VERSION "0.0"

NS_ :

                BA_DiEF_
                BA_
                CAT_DEF_
                CAT_
                FILTER
                BA_DEF_DEF_
                EV_DATA_
                ENVVAR_DATA_
                SGTYPE_
                SGTYPE_VAL_
                BA_DEF_SGTYPE_
                BA_SGTYPE_
                SIG_TYPE_REF_
                VAL_TABLE_
                SIG_GROUP_
                SIG_VALTYPE_
                SIGTYPE_VALTYPE_
                BO_TX_BU_
                BA_DEF_REL_
                BA_REL_
                BA_DEF_DEF_REL_
                BU_SG_REL_
                BU_EV_REL_
                BU_BO_REL_
                SG_MUL_VAL_

		NS_DESC_
                CM_
                BA_DEF_
                BA_
                CAT_DEF_
                CAT_
                FILTER
                BA_DEF_DEF_
                EV_DATA_
                ENVVAR_DATA_
                SGTYPE_
                SGTYPE_VAL_
                BA_DEF_SGTYPE_
                BA_SGTYPE_
                SIG_TYPE_REF_
                VAL_TABLE_
                SIG_GROUP_
                SIG_VALTYPE_
                SIGTYPE_VALTYPE_
                BO_TX_BU_
                BA_DEF_REL_
                BA_REL_
                BA_DEF_DEF_REL_
                BU_SG_REL_
                BU_EV_REL_
                BU_BO_REL_
                SG_MUL_VAL_

		NS_DESC_
                CM_
                BA_DEF_
                BA_
                CAT_DEF_
                CAT_
                FILTER
                BA_DEF_DEF_
                EV_DATA_
                ENVVAR_DATA_
                SGTYPE_
                SGTYPE_VAL_
                BA_DEF_SGTYPE_
                BA_SGTYPE_
                SIG_TYPE_REF_
                VAL_TABLE_
                SIG_GROUP_
                SIG_VALTYPE_
                SIGTYPE_VALTYPE_
                BO_TX_BU_
                BA_DEF_REL_
                BA_REL_
                BA_DEF_DEF_REL_
                BU_SG_REL_
                BU_EV_REL_
                BU_BO_REL_
                SG_MUL_VAL_

BS_:

BU_:

BO_ 1024 MC_Identification: 8 Vector__XXX
        SG_ Prohelion_ID : 0|32@1+ (1,0) [0|0] "" Vector__XXX
        SG_ Serial_Number : 32|32@1+ (1,0) [0|0] "" Vector__XXX

BO_ 1025 MC_Status: 8 Vector__XXX
        SG_ Output_Voltage_PWM_Limit : 0|1@1+ (1,0) [0|0] "" Vector__XXX
        SG_ Motor_Current_Limit : 1|1@1+ (1,0) [0|0] "" Vector__XXX
        SG_ Velocity_Limit : 2|1@1+ (1,0) [0|0] "" Vector__XXX
        SG_ Bus_Current_Limit : 3|1@1+ (1,0) [0|0] "" Vector__XXX
        SG_ Bus_Voltage_U_Limit : 4|1@1+ (1,0) [0|0] "" Vector__XXX
        SG_ Bus_Voltage_L_Limit : 5|1@1+ (1,0) [0|0] "" Vector__XXX
        SG_ Motor_Temperature_Limit : 6|1@1+ (1,0) [0|0] "" Vector__XXX
        SG_ Hardware_Over_Current : 16|1@1+ (1,0) [0|0] "" Vector__XXX
        SG_ Software_Over_Current : 17|1@1+ (1,0) [0|0] "" Vector__XXX
        SG_ Bus_Overvoltage : 18|1@1+ (1,0) [0|0] "" Vector__XXX
        SG_ Bad_Hall_Sequence : 19|1@1+ (1,0) [0|0] "" Vector__XXX
        SG_ Watchdog_Reset : 20|1@1+ (1,0) [0|0] "" Vector__XXX
        SG_ Config_Read_Error : 21|1@1+ (1,0) [0|0] "" Vector__XXX
        SG_ UVLO_15V : 22|1@1+ (1,0) [0|0] "" Vector__XXX
        SG_ Desaturation_Fault : 23|1@1+ (1,0) [0|0] "" Vector__XXX
        SG_ Motor_Over_Speed : 24|1@1+ (1,0) [0|0] "" Vector__XXX
        SG_ Active_Motor : 32|16@1+ (1,0) [0|0] "" Vector__XXX
        SG_ Transmit_Error_Count : 48|8@1+ (1,0) [0|0] "" Vector__XXX
        SG_ Receive_Error_Count : 56|8@1+ (1,0) [0|0] "" Vector__XXX

BO_ 1026 MC_Bus_Measurement: 8 Vector__XXX
        SG_ Bus_Voltage : 0|32@1+ (1,0) [0|0] "Volt" Vector__XXX
        SG_ Bus_Current : 32|32@1+ (1,0) [0|0] "Ampere" Vector__XXX

BO_ 1027 MC_Velocity: 8 Vector__XXX
        SG_ Motor_Velocity : 0|32@1+ (1,0) [0|0] "RPM" Vector__XXX
        SG_ Vehicle_Velocity : 32|32@1+ (1,0) [0|0] "m/s" Vector__XXX

BO_ 1028 MC_Phase_Current: 8 Vector__XXX
        SG_ PhaseC_Current_Val : 32|32@1+ (1,0) [0|0] "Ampere" Vector__XXX
        SG_ PhaseB_Current_Val : 0|32@1+ (1,0) [0|0] "Ampere" Vector__XXX

BO_ 1029 MC_Motor_Voltage_Vector: 8 Vector__XXX
        SG_ Vq : 0|32@1+ (1,0) [0|0] "Volt" Vector__XXX
        SG_ Vd : 32|32@1+ (1,0) [0|0] "Volt" Vector__XXX

BO_ 1030 MC_Motor_Current_Vector: 8 Vector__XXX
        SG_ Iq : 0|32@1+ (1,0) [0|0] "Ampere" Vector__XXX
        SG_ Id : 32|32@1+ (1,0) [0|0] "Ampere" Vector__XXX

BO_ 1031 MC_BackEMF: 8 Vector__XXX
        SG_ BEMFq : 0|32@1+ (1,0) [0|0] "Volt" Vector__XXX
        SG_ BEMFd : 32|32@1+ (1,0) [0|0] "Volt" Vector__XXX

BO_ 1032 MC_Voltage_Rail_15V: 8 Vector__XXX
        SG_ Supply_15V : 32|32@1+ (1,0) [0|0] "Volt" Vector__XXX

BO_ 1033 MC_Voltage_Rail_3V3_1V9: 8 Vector__XXX
        SG_ Supply_1V9 : 0|32@1+ (1,0) [0|0] "" Vector__XXX
        SG_ Supply_3V3 : 32|32@1+ (1,0) [0|0] "" Vector__XXX

BO_ 1035 MC_HeatSink_Motor_Temperature: 8 Vector__XXX
        SG_ Motor_Temp : 0|32@1+ (1,0) [0|0] "Celcius" Vector__XXX
        SG_ Heat_Sink_Temp : 32|32@1+ (1,0) [0|0] "Celcius" Vector__XXX

BO_ 1036 MC_DSP_Temperature: 8 Vector__XXX
        SG_ DSP_Board_Temperature : 0|32@1+ (1,0) [0|0] "Celcius" Vector__XXX

BO_ 1038 MC_Odometer_Charge: 8 Vector__XXX
        SG_ Odometer : 0|32@1+ (1,0) [0|0] "meter" Vector__XXX
        SG_ DC_Bus_AmpHours : 32|32@1+ (1,0) [0|0] "Ah" Vector__XXX

BO_ 1047 MC_Slip_Speed: 8 Vector__XXX
        SG_ Slip_Speed : 32|32@1+ (1,0) [0|0] "Hz" Vector__XXX

BO_ 1042 MC_Active_Motor_Change: 8 Vector__XXX
        SG_ Config_Key : 0|32@1+ (1,0) [0|0] "" Vector__XXX
        SG_ Active_Motor : 32|32@1+ (1,0) [0|0] "" Vector__XXX

BO_ 1696 MPPT1_Input_Measurements: 8 Vector__XXX
        SG_ Input_Voltage_A : 0|32@1+ (1,0) [0|0] "Volt" Vector__XXX
        SG_ Input_Current_A : 32|32@1+ (1,0) [0|0] "Ampere" Vector__XXX

BO_ 1697 MPPT1_Output_Measurements: 8 Vector__XXX
        SG_ Output_Voltage_A : 0|32@1+ (1,0) [0|0] "Volt" Vector__XXX
        SG_ Output_Current_A : 32|32@1+ (1,0) [0|0] "Ampere" Vector__XXX

BO_ 1698 MPPT1_Temperature: 8 Vector__XXX
        SG_ MOSFET_Temp_A : 0|32@1+ (1,0) [0|0] "Celcius" Vector__XXX
        SG_ Controller_Temp_A : 32|32@1+ (1,0) [0|0] "" Vector__XXX

BO_ 1699 MPPT1_Auxiliary_PS: 8 Vector__XXX
        SG_ Supply_12V_A : 0|32@1+ (1,0) [0|0] "Volt" Vector__XXX
        SG_ Supply_3V_A : 32|32@1+ (1,0) [0|0] "Volt" Vector__XXX

BO_ 1700 MPPT1_Limits: 8 Vector__XXX
        SG_ Max_Out_Volt_A : 0|32@1+ (1,0) [0|0] "Volt" Vector__XXX
        SG_ Max_In_Current_A : 32|32@1+ (1,0) [0|0] "Ampere" Vector__XXX

BO_ 1701 MPPT1_Status: 8 Vector__XXX
        SG_ RX_Error_Count_A : 0|8@1+ (1,0) [0|0] "" Vector__XXX
        SG_ TX_Error_Count_A : 8|8@1+ (1,0) [0|0] "" Vector__XXX
        SG_ TX_Overflow_Count_A : 16|8@1+ (1,0) [0|0] "" Vector__XXX
        SG_ Low_Array_Power_A : 24|1@1+ (1,0) [0|0] "" Vector__XXX
        SG_ Mosfet_Overheat_A : 25|1@1+ (1,0) [0|0] "" Vector__XXX
        SG_ Battery_Low_A : 26|1@1+ (1,0) [0|0] "" Vector__XXX
        SG_ Battery_Full_A : 27|1@1+ (1,0) [0|0] "" Vector__XXX
        SG_ Undervoltage_12V_A : 28|1@1+ (1,0) [0|0] "" Vector__XXX
        SG_ HW_Overcurrent_A : 30|1@1+ (1,0) [0|0] "" Vector__XXX
        SG_ HW_Overvoltage_A : 31|1@1+ (1,0) [0|0] "" Vector__XXX
        SG_ Input_Currnet_Min_A : 32|1@1+ (1,0) [0|0] "" Vector__XXX
        SG_ Input_Current_Max_A : 33|1@1+ (1,0) [0|0] "" Vector__XXX
        SG_ Output_Voltage_Max_A : 34|1@1+ (1,0) [0|0] "" Vector__XXX
        SG_ MOSFET_Temperature_A : 35|1@1+ (1,0) [0|0] "" Vector__XXX
        SG_ Duty_Cycle_Min_A : 36|1@1+ (1,0) [0|0] "" Vector__XXX
        SG_ Duty_Cycle_Max_A : 37|1@1+ (1,0) [0|0] "" Vector__XXX
        SG_ Local_MPPT_A : 38|1@1+ (1,0) [0|0] "" Vector__XXX
        SG_ Global_MPPT_A : 39|1@1+ (1,0) [0|0] "" Vector__XXX
        SG_ Mode_A : 40|8@1+ (1,0) [0|0] "" Vector__XXX
        SG_ Test_Counter_A : 56|8@1+ (1,0) [0|0] "" Vector__XXX

BO_ 1702 MPPT1_Power_Connector: 8 Vector__XXX
        SG_ Battery_Side_Output_Voltage_A : 0|32@1+ (1,0) [0|0] "Volt" Vector__XXX
        SG_ Power_Connector_Temperature_A : 32|32@1+ (1,0) [0|0] "Celcius" Vector__XXX

BO_ 1704 MPPT1_Mode_Set: 1 Vector__XXX
        SG_ Set_Mode_A : 0|8@1+ (1,0) [0|0] "" Vector__XXX

BO_ 1706 MPPT1_Maximum_Output_Volt: 4 Vector__XXX
        SG_ Max_Output_Voltage_Set_A : 0|32@1+ (1,0) [0|0] "Volt" Vector__XXX

BO_ 1707 MPPT1_Maximum_Input_Current: 4 Vector__XXX
        SG_ Max_Input_Current_Set_A : 0|32@1+ (1,0) [0|0] "Ampere" Vector__XXX

BO_ 1712 MPPT2_Input_Measurements: 8 Vector__XXX
        SG_ Input_Voltage_B : 0|32@1+ (1,0) [0|0] "Volt" Vector__XXX
        SG_ Input_Current_B : 32|32@1+ (1,0) [0|0] "Ampere" Vector__XXX

BO_ 1713 MPPT2_Output_Measurements: 8 Vector__XXX
        SG_ Output_Voltage_B : 0|32@1+ (1,0) [0|0] "Volt" Vector__XXX
        SG_ Output_Current_B : 32|32@1+ (1,0) [0|0] "Ampere" Vector__XXX

BO_ 1714 MPPT2_Temperature: 8 Vector__XXX
        SG_ MOSFET_Temp_B : 0|32@1+ (1,0) [0|0] "Celcius" Vector__XXX
        SG_ Controller_Temp_B : 32|32@1+ (1,0) [0|0] "" Vector__XXX

BO_ 1715 MPPT2_Auxiliary_PS: 8 Vector__XXX
        SG_ Supply_12V_B : 0|32@1+ (1,0) [0|0] "Volt" Vector__XXX
        SG_ Supply_3V_B : 32|32@1+ (1,0) [0|0] "Volt" Vector__XXX

BO_ 1716 MPPT2_Limits: 8 Vector__XXX
        SG_ Max_Out_Volt_B : 0|32@1+ (1,0) [0|0] "Volt" Vector__XXX
        SG_ Max_In_Current_B : 32|32@1+ (1,0) [0|0] "Ampere" Vector__XXX

BO_ 1717 MPPT2_Status: 8 Vector__XXX
        SG_ RX_Error_Count_B : 0|8@1+ (1,0) [0|0] "" Vector__XXX
        SG_ TX_Error_Count_B : 8|8@1+ (1,0) [0|0] "" Vector__XXX
        SG_ TX_Overflow_Count_B : 16|8@1+ (1,0) [0|0] "" Vector__XXX
        SG_ Low_Array_Power_B : 24|1@1+ (1,0) [0|0] "" Vector__XXX
        SG_ Mosfet_Overheat_B : 25|1@1+ (1,0) [0|0] "" Vector__XXX
        SG_ Battery_Low_B : 26|1@1+ (1,0) [0|0] "" Vector__XXX
        SG_ Undervoltage_12V_B : 28|1@1+ (1,0) [0|0] "" Vector__XXX
        SG_ Battery_Full_B : 27|1@1+ (1,0) [0|0] "" Vector__XXX
        SG_ HW_Overcurrent_B : 30|1@1+ (1,0) [0|0] "" Vector__XXX
        SG_ HW_Overvoltage_B : 31|1@1+ (1,0) [0|0] "" Vector__XXX
        SG_ Input_Currnet_Min_B : 32|1@1+ (1,0) [0|0] "" Vector__XXX
        SG_ Input_Current_Max_B : 33|1@1+ (1,0) [0|0] "" Vector__XXX
        SG_ Output_Voltage_Max_B : 34|1@1+ (1,0) [0|0] "" Vector__XXX
        SG_ MOSFET_Temperature_B : 35|1@1+ (1,0) [0|0] "" Vector__XXX
        SG_ Duty_Cycle_Min_B : 36|1@1+ (1,0) [0|0] "" Vector__XXX
        SG_ Duty_Cycle_Max_B : 37|1@1+ (1,0) [0|0] "" Vector__XXX
        SG_ Local_MPPT_B : 38|1@1+ (1,0) [0|0] "" Vector__XXX
        SG_ Global_MPPT_B : 39|1@1+ (1,0) [0|0] "" Vector__XXX
        SG_ Mode_B : 40|8@1+ (1,0) [0|0] "" Vector__XXX
        SG_ Test_Counter_B : 56|8@1+ (1,0) [0|0] "" Vector__XXX

BO_ 1718 MPPT2_Power_Connector: 8 Vector__XXX
        SG_ Battery_Side_Output_Voltage_B : 0|32@1+ (1,0) [0|0] "Volt" Vector__XXX
        SG_ Power_Connector_Temperature_B : 32|32@1+ (1,0) [0|0] "Celcius" Vector__XXX

BO_ 1720 MPPT2_Mode_Set: 1 Vector__XXX
        SG_ Set_Mode_B : 0|8@1+ (1,0) [0|0] "" Vector__XXX

BO_ 1722 MPPT2_Maximum_Output_Volt: 4 Vector__XXX
        SG_ Max_Output_Voltage_Set_B : 0|32@1+ (1,0) [0|0] "Volt" Vector__XXX

BO_ 1723 MPPT2_Maximum_Input_Current: 4 Vector__XXX
        SG_ Max_Input_Current_Set_B : 0|32@1+ (1,0) [0|0] "Ampere" Vector__XXX

BO_ 1728 MPPT3_Input_Measurements: 8 Vector__XXX
        SG_ Input_Voltage_C : 0|32@1+ (1,0) [0|0] "Volt" Vector__XXX
        SG_ Input_Current_C : 32|32@1+ (1,0) [0|0] "Ampere" Vector__XXX

BO_ 1729 MPPT3_Output_Measurements: 8 Vector__XXX
        SG_ Output_Voltage_C : 0|32@1+ (1,0) [0|0] "Volt" Vector__XXX
        SG_ Output_Current_C : 32|32@1+ (1,0) [0|0] "Ampere" Vector__XXX

BO_ 1730 MPPT3_Temperature: 8 Vector__XXX
        SG_ MOSFET_Temp_C : 0|32@1+ (1,0) [0|0] "Celcius" Vector__XXX
        SG_ Controller_Temp_C : 32|32@1+ (1,0) [0|0] "" Vector__XXX

BO_ 1731 MPPT3_Auxiliary_PS: 8 Vector__XXX
        SG_ Supply_12V_C : 0|32@1+ (1,0) [0|0] "Volt" Vector__XXX
        SG_ Supply_3V_C : 32|32@1+ (1,0) [0|0] "Volt" Vector__XXX

BO_ 1732 MPPT3_Limits: 8 Vector__XXX
        SG_ Max_Out_Volt_C : 0|32@1+ (1,0) [0|0] "Volt" Vector__XXX
        SG_ Max_In_Current_C : 32|32@1+ (1,0) [0|0] "Ampere" Vector__XXX

BO_ 1733 MPPT3_Status: 8 Vector__XXX
        SG_ RX_Error_Count_C : 0|8@1+ (1,0) [0|0] "" Vector__XXX
        SG_ TX_Error_Count_C : 8|8@1+ (1,0) [0|0] "" Vector__XXX
        SG_ TX_Overflow_Count_C : 16|8@1+ (1,0) [0|0] "" Vector__XXX
        SG_ Low_Array_Power_C : 24|1@1+ (1,0) [0|0] "" Vector__XXX
        SG_ Mosfet_Overheat_C : 25|1@1+ (1,0) [0|0] "" Vector__XXX
        SG_ Battery_Low_C : 26|1@1+ (1,0) [0|0] "" Vector__XXX
        SG_ Undervoltage_12V_C : 28|1@1+ (1,0) [0|0] "" Vector__XXX
        SG_ Battery_Full_C : 27|1@1+ (1,0) [0|0] "" Vector__XXX
        SG_ HW_Overcurrent_C : 30|1@1+ (1,0) [0|0] "" Vector__XXX
        SG_ HW_Overvoltage_C : 31|1@1+ (1,0) [0|0] "" Vector__XXX
        SG_ Input_Currnet_Min_C : 32|1@1+ (1,0) [0|0] "" Vector__XXX
        SG_ Input_Current_Max_C : 33|1@1+ (1,0) [0|0] "" Vector__XXX
        SG_ Output_Voltage_Max_C : 34|1@1+ (1,0) [0|0] "" Vector__XXX
        SG_ MOSFET_Temperature_C : 35|1@1+ (1,0) [0|0] "" Vector__XXX
        SG_ Duty_Cycle_Min_C : 36|1@1+ (1,0) [0|0] "" Vector__XXX
        SG_ Duty_Cycle_Max_C : 37|1@1+ (1,0) [0|0] "" Vector__XXX
        SG_ Local_MPPT_C : 38|1@1+ (1,0) [0|0] "" Vector__XXX
        SG_ Global_MPPT_C : 39|1@1+ (1,0) [0|0] "" Vector__XXX
        SG_ Mode_C : 40|8@1+ (1,0) [0|0] "" Vector__XXX
        SG_ Test_Counter_C : 56|8@1+ (1,0) [0|0] "" Vector__XXX

BO_ 1734 MPPT3_Power_Connector: 8 Vector__XXX
        SG_ Battery_Side_Output_Voltage_C : 0|32@1+ (1,0) [0|0] "Volt" Vector__XXX
        SG_ Power_Connector_Temperature_C : 32|32@1+ (1,0) [0|0] "Celcius" Vector__XXX

BO_ 1736 MPPT3_Mode_Set: 1 Vector__XXX
        SG_ Set_Mode_C : 0|8@1+ (1,0) [0|0] "" Vector__XXX

BO_ 1738 MPPT3_Maximum_Output_Volt: 4 Vector__XXX
        SG_ Max_Output_Voltage_Set_C : 0|32@1+ (1,0) [0|0] "Volt" Vector__XXX

BO_ 1739 MPPT3_Maximum_Input_Current: 4 Vector__XXX
        SG_ Max_Input_Current_Set_C : 0|32@1+ (1,0) [0|0] "Ampere" Vector__XXX

BO_ 1744 MPPT4_Input_Measurements: 8 Vector__XXX
        SG_ Input_Voltage_D : 0|32@1+ (1,0) [0|0] "Volt" Vector__XXX
        SG_ Input_Current_D : 32|32@1+ (1,0) [0|0] "Ampere" Vector__XXX

BO_ 1745 MPPT4_Output_Measurements: 8 Vector__XXX
        SG_ Output_Voltage_D : 0|32@1+ (1,0) [0|0] "Volt" Vector__XXX
        SG_ Output_Current_D : 32|32@1+ (1,0) [0|0] "Ampere" Vector__XXX

BO_ 1746 MPPT4_Temperature: 8 Vector__XXX
        SG_ MOSFET_Temp_D : 0|32@1+ (1,0) [0|0] "Celcius" Vector__XXX
        SG_ Controller_Temp_D : 32|32@1+ (1,0) [0|0] "" Vector__XXX

BO_ 1747 MPPT4_Auxiliary_PS: 8 Vector__XXX
        SG_ Supply_12V_D : 0|32@1+ (1,0) [0|0] "Volt" Vector__XXX
        SG_ Supply_3V_D : 32|32@1+ (1,0) [0|0] "Volt" Vector__XXX

BO_ 1748 MPPT4_Limits: 8 Vector__XXX
        SG_ Max_Out_Volt_D : 0|32@1+ (1,0) [0|0] "Volt" Vector__XXX
        SG_ Max_In_Current_D : 32|32@1+ (1,0) [0|0] "Ampere" Vector__XXX

BO_ 1749 MPPT4_Status: 8 Vector__XXX
        SG_ RX_Error_Count_D : 0|8@1+ (1,0) [0|0] "" Vector__XXX
        SG_ TX_Error_Count_D : 8|8@1+ (1,0) [0|0] "" Vector__XXX
        SG_ TX_Overflow_Count_D : 16|8@1+ (1,0) [0|0] "" Vector__XXX
        SG_ Low_Array_Power_D : 24|1@1+ (1,0) [0|0] "" Vector__XXX
        SG_ Mosfet_Overheat_D : 25|1@1+ (1,0) [0|0] "" Vector__XXX
        SG_ Battery_Low_D : 26|1@1+ (1,0) [0|0] "" Vector__XXX
        SG_ Undervoltage_12V_D : 28|1@1+ (1,0) [0|0] "" Vector__XXX
        SG_ Battery_Full_D : 27|1@1+ (1,0) [0|0] "" Vector__XXX
        SG_ HW_Overcurrent_D : 30|1@1+ (1,0) [0|0] "" Vector__XXX
        SG_ HW_Overvoltage_D : 31|1@1+ (1,0) [0|0] "" Vector__XXX
        SG_ Input_Currnet_Min_D : 32|1@1+ (1,0) [0|0] "" Vector__XXX
        SG_ Input_Current_Max_D : 33|1@1+ (1,0) [0|0] "" Vector__XXX
        SG_ Output_Voltage_Max_D : 34|1@1+ (1,0) [0|0] "" Vector__XXX
        SG_ MOSFET_Temperature_D : 35|1@1+ (1,0) [0|0] "" Vector__XXX
        SG_ Duty_Cycle_Min_D : 36|1@1+ (1,0) [0|0] "" Vector__XXX
        SG_ Duty_Cycle_Max_D : 37|1@1+ (1,0) [0|0] "" Vector__XXX
        SG_ Local_MPPT_D : 38|1@1+ (1,0) [0|0] "" Vector__XXX
        SG_ Global_MPPT_D : 39|1@1+ (1,0) [0|0] "" Vector__XXX
        SG_ Mode_D : 40|8@1+ (1,0) [0|0] "" Vector__XXX
        SG_ Test_Counter_D : 56|8@1+ (1,0) [0|0] "" Vector__XXX

BO_ 1750 MPPT4_Power_Connector: 8 Vector__XXX
        SG_ Battery_Side_Output_Voltage_D : 0|32@1+ (1,0) [0|0] "Volt" Vector__XXX
        SG_ Power_Connector_Temperature_D : 32|32@1+ (1,0) [0|0] "Celcius" Vector__XXX

BO_ 1752 MPPT4_Mode_Set: 1 Vector__XXX
        SG_ Set_Mode_D : 0|8@1+ (1,0) [0|0] "" Vector__XXX

BO_ 1754 MPPT4_Maximum_Output_Volt: 4 Vector__XXX
        SG_ Max_Output_Voltage_Set_D : 0|32@1+ (1,0) [0|0] "Volt" Vector__XXX

BO_ 1755 MPPT4_Maximum_Input_Current: 4 Vector__XXX
        SG_ Max_Input_Current_Set_D : 0|32@1+ (1,0) [0|0] "Ampere" Vector__XXX

BO_ 1285 Driver_Controls: 8 Vector__XXX
        SG_ State : 0|16@1+ (1,0) [0|0] "" Vector__XXX

BO_ 1536 Heartbeat: 8 Vector__XXX
	SG_ Device_ID : 0|32@1+ (1,0) [0|0] "" Vector__XXX
	SG_ Serial_No : 32|32@1+ (1,0) [0|0] "" Vector__XXX

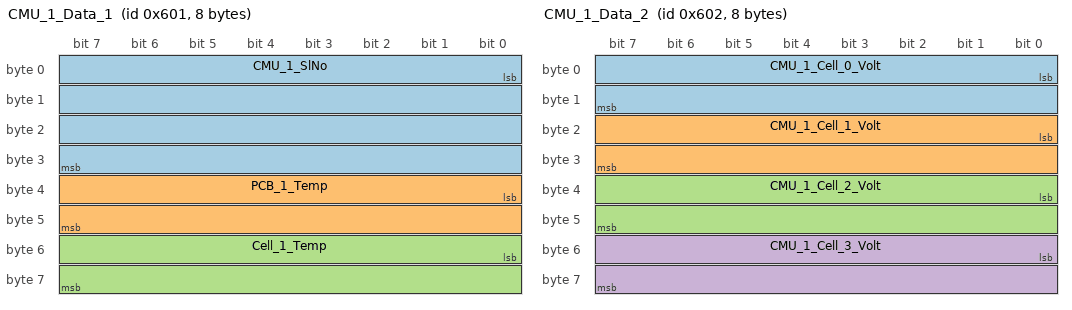
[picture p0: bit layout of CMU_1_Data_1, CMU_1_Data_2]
BO_ 1537 CMU_1_Data_1: 8 Vector__XXX
        SG_ CMU_1_SlNo : 0|32@1+ (1,0) [0|0] "" Vector__XXX
        SG_ PCB_1_Temp : 32|16@1+ (0.1,0) [0|0] "Celcius" Vector__XXX
        SG_ Cell_1_Temp : 48|16@1+ (0.1,0) [0|0] "Celcius" Vector__XXX

BO_ 1538 CMU_1_Data_2: 8 Vector__XXX
        SG_ CMU_1_Cell_0_Volt : 0|16@1+ (1,0) [0|0] "mV" Vector__XXX
        SG_ CMU_1_Cell_1_Volt : 16|16@1+ (1,0) [0|0] "mV" Vector__XXX
        SG_ CMU_1_Cell_2_Volt : 32|16@1+ (1,0) [0|0] "mV" Vector__XXX
        SG_ CMU_1_Cell_3_Volt : 48|16@1+ (1,0) [0|0] "mV" Vector__XXX

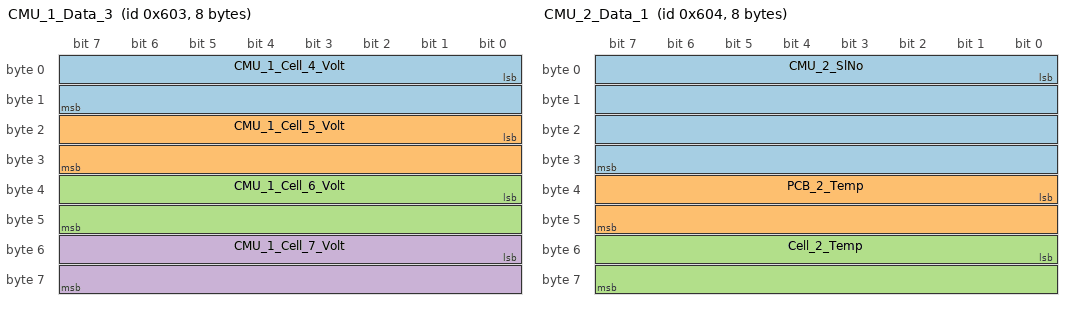
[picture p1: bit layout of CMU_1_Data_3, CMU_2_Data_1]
BO_ 1539 CMU_1_Data_3: 8 Vector__XXX
        SG_ CMU_1_Cell_4_Volt : 0|16@1+ (1,0) [0|0] "mV" Vector__XXX
        SG_ CMU_1_Cell_5_Volt : 16|16@1+ (1,0) [0|0] "mV" Vector__XXX
        SG_ CMU_1_Cell_6_Volt : 32|16@1+ (1,0) [0|0] "mV" Vector__XXX
        SG_ CMU_1_Cell_7_Volt : 48|16@1+ (1,0) [0|0] "mV" Vector__XXX

BO_ 1540 CMU_2_Data_1: 8 Vector__XXX
        SG_ CMU_2_SlNo : 0|32@1+ (1,0) [0|0] "" Vector__XXX
        SG_ PCB_2_Temp : 32|16@1+ (0.1,0) [0|0] "Celcius" Vector__XXX
        SG_ Cell_2_Temp : 48|16@1+ (0.1,0) [0|0] "Celcius" Vector__XXX

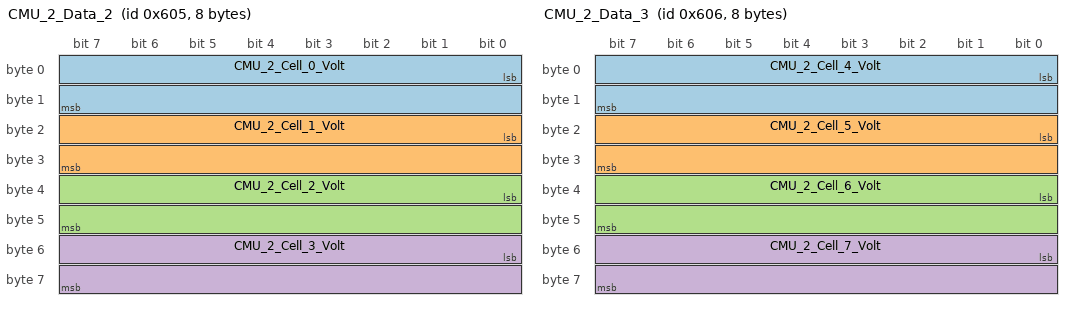
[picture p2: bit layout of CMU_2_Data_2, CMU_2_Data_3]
BO_ 1541 CMU_2_Data_2: 8 Vector__XXX
        SG_ CMU_2_Cell_0_Volt : 0|16@1+ (1,0) [0|0] "mV" Vector__XXX
        SG_ CMU_2_Cell_1_Volt : 16|16@1+ (1,0) [0|0] "mV" Vector__XXX
        SG_ CMU_2_Cell_2_Volt : 32|16@1+ (1,0) [0|0] "mV" Vector__XXX
        SG_ CMU_2_Cell_3_Volt : 48|16@1+ (1,0) [0|0] "mV" Vector__XXX

BO_ 1542 CMU_2_Data_3: 8 Vector__XXX
        SG_ CMU_2_Cell_4_Volt : 0|16@1+ (1,0) [0|0] "mV" Vector__XXX
        SG_ CMU_2_Cell_5_Volt : 16|16@1+ (1,0) [0|0] "mV" Vector__XXX
        SG_ CMU_2_Cell_6_Volt : 32|16@1+ (1,0) [0|0] "mV" Vector__XXX
        SG_ CMU_2_Cell_7_Volt : 48|16@1+ (1,0) [0|0] "mV" Vector__XXX

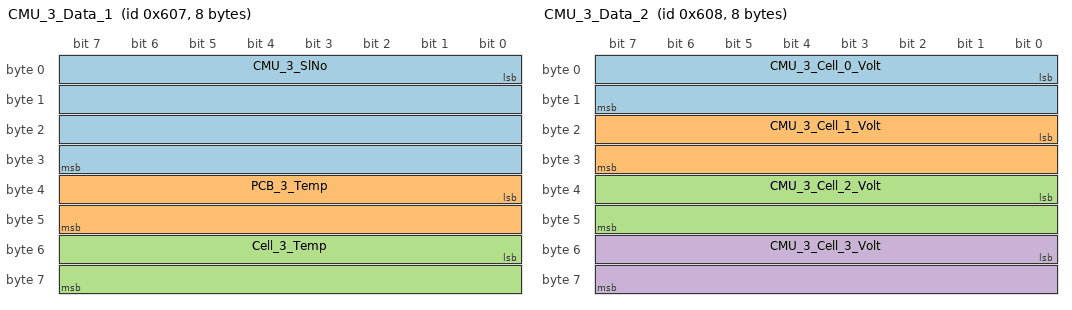
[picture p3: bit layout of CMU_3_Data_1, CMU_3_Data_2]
BO_ 1543 CMU_3_Data_1: 8 Vector__XXX
        SG_ CMU_3_SlNo : 0|32@1+ (1,0) [0|0] "" Vector__XXX
        SG_ PCB_3_Temp : 32|16@1+ (0.1,0) [0|0] "Celcius" Vector__XXX
        SG_ Cell_3_Temp : 48|16@1+ (0.1,0) [0|0] "Celcius" Vector__XXX

BO_ 1544 CMU_3_Data_2: 8 Vector__XXX
        SG_ CMU_3_Cell_0_Volt : 0|16@1+ (1,0) [0|0] "mV" Vector__XXX
        SG_ CMU_3_Cell_1_Volt : 16|16@1+ (1,0) [0|0] "mV" Vector__XXX
        SG_ CMU_3_Cell_2_Volt : 32|16@1+ (1,0) [0|0] "mV" Vector__XXX
        SG_ CMU_3_Cell_3_Volt : 48|16@1+ (1,0) [0|0] "mV" Vector__XXX

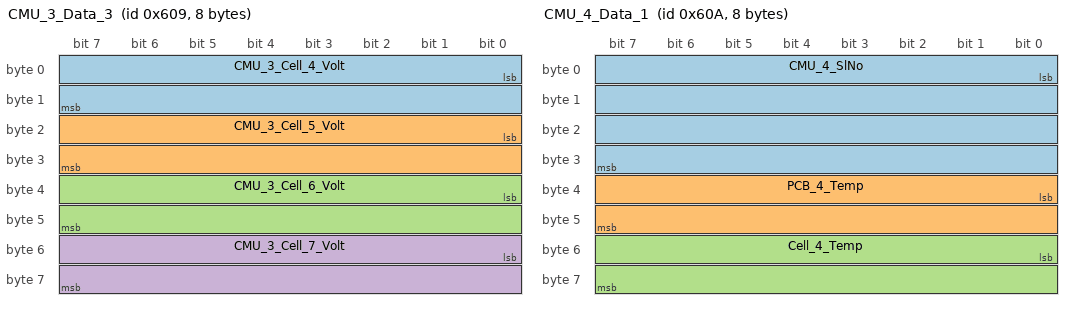
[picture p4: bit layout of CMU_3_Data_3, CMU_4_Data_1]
BO_ 1545 CMU_3_Data_3: 8 Vector__XXX
        SG_ CMU_3_Cell_4_Volt : 0|16@1+ (1,0) [0|0] "mV" Vector__XXX
        SG_ CMU_3_Cell_5_Volt : 16|16@1+ (1,0) [0|0] "mV" Vector__XXX
        SG_ CMU_3_Cell_6_Volt : 32|16@1+ (1,0) [0|0] "mV" Vector__XXX
        SG_ CMU_3_Cell_7_Volt : 48|16@1+ (1,0) [0|0] "mV" Vector__XXX

BO_ 1546 CMU_4_Data_1: 8 Vector__XXX
        SG_ CMU_4_SlNo : 0|32@1+ (1,0) [0|0] "" Vector__XXX
        SG_ PCB_4_Temp : 32|16@1+ (0.1,0) [0|0] "Celcius" Vector__XXX
        SG_ Cell_4_Temp : 48|16@1+ (0.1,0) [0|0] "Celcius" Vector__XXX

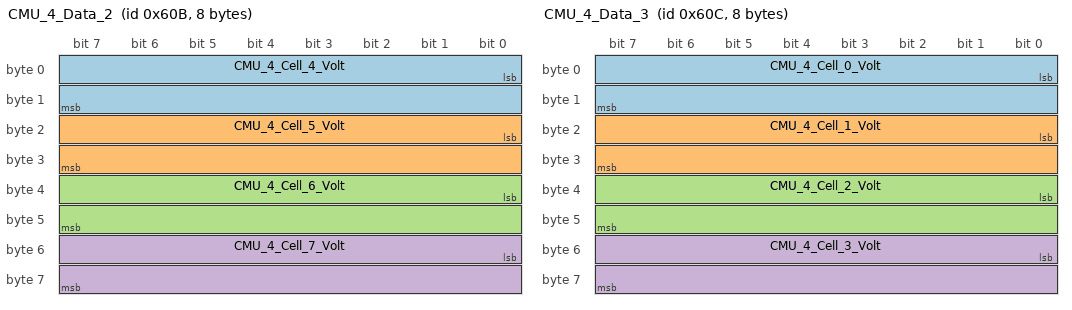
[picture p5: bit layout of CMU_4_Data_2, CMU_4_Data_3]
BO_ 1547 CMU_4_Data_2: 8 Vector__XXX
        SG_ CMU_4_Cell_4_Volt : 0|16@1+ (1,0) [0|0] "mV" Vector__XXX
        SG_ CMU_4_Cell_5_Volt : 16|16@1+ (1,0) [0|0] "mV" Vector__XXX
        SG_ CMU_4_Cell_6_Volt : 32|16@1+ (1,0) [0|0] "mV" Vector__XXX
        SG_ CMU_4_Cell_7_Volt : 48|16@1+ (1,0) [0|0] "mV" Vector__XXX

BO_ 1548 CMU_4_Data_3: 8 Vector__XXX
        SG_ CMU_4_Cell_0_Volt : 0|16@1+ (1,0) [0|0] "mV" Vector__XXX
        SG_ CMU_4_Cell_1_Volt : 16|16@1+ (1,0) [0|0] "mV" Vector__XXX
        SG_ CMU_4_Cell_2_Volt : 32|16@1+ (1,0) [0|0] "mV" Vector__XXX
        SG_ CMU_4_Cell_3_Volt : 48|16@1+ (1,0) [0|0] "mV" Vector__XXX

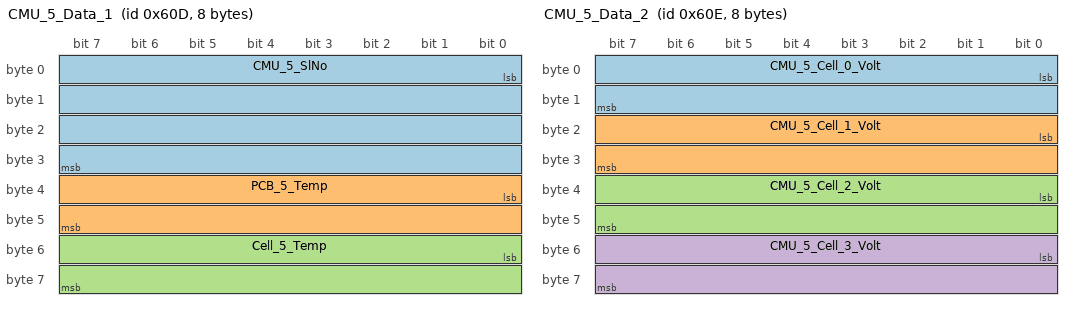
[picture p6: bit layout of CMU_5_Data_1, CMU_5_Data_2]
BO_ 1549 CMU_5_Data_1: 8 Vector__XXX
        SG_ CMU_5_SlNo : 0|32@1+ (1,0) [0|0] "" Vector__XXX
        SG_ PCB_5_Temp : 32|16@1+ (0.1,0) [0|0] "Celcius" Vector__XXX
        SG_ Cell_5_Temp : 48|16@1+ (0.1,0) [0|0] "Celcius" Vector__XXX

BO_ 1550 CMU_5_Data_2: 8 Vector__XXX
        SG_ CMU_5_Cell_0_Volt : 0|16@1+ (1,0) [0|0] "mV" Vector__XXX
        SG_ CMU_5_Cell_1_Volt : 16|16@1+ (1,0) [0|0] "mV" Vector__XXX
        SG_ CMU_5_Cell_2_Volt : 32|16@1+ (1,0) [0|0] "mV" Vector__XXX
        SG_ CMU_5_Cell_3_Volt : 48|16@1+ (1,0) [0|0] "mV" Vector__XXX

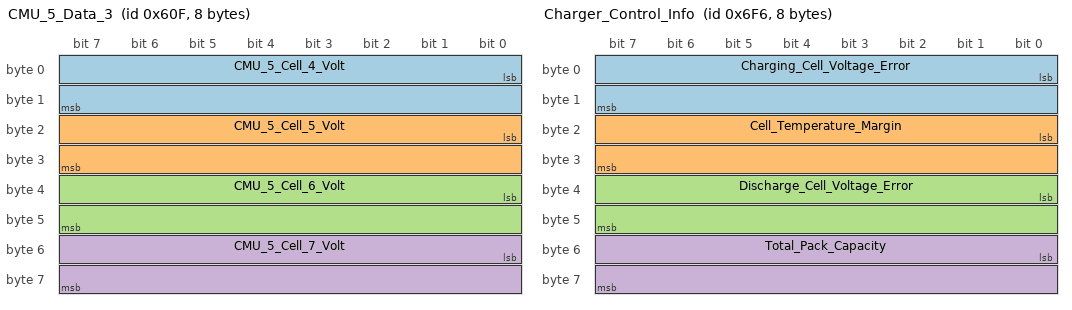
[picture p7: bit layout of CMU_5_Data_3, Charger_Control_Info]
BO_ 1551 CMU_5_Data_3: 8 Vector__XXX
        SG_ CMU_5_Cell_4_Volt : 0|16@1+ (1,0) [0|0] "mV" Vector__XXX
        SG_ CMU_5_Cell_5_Volt : 16|16@1+ (1,0) [0|0] "mV" Vector__XXX
        SG_ CMU_5_Cell_6_Volt : 32|16@1+ (1,0) [0|0] "mV" Vector__XXX
        SG_ CMU_5_Cell_7_Volt : 48|16@1+ (1,0) [0|0] "mV" Vector__XXX

BO_ 1780 Pack_SOC: 8 Vector__XXX
        SG_ SOC_Ah : 0|32@1+ (1,0) [0|0] "Ah" Vector__XXX
        SG_ SOC_Percent : 32|32@1+ (1,0) [0|0] "Percent" Vector__XXX

BO_ 1781 Balance_SOC: 8 Vector__XXX
        SG_ SOC_Ah : 0|32@1+ (1,0) [0|0] "Ah" Vector__XXX
        SG_ SOC_Percent : 32|32@1+ (1,0) [0|0] "Percent" Vector__XXX

BO_ 1782 Charger_Control_Info: 8 Vector__XXX
        SG_ Charging_Cell_Voltage_Error : 0|16@1+ (1,0) [0|0] "mV" Vector__XXX
        SG_ Cell_Temperature_Margin : 16|16@1+ (0.1,0) [0|0] "Celcius" Vector__XXX
        SG_ Discharge_Cell_Voltage_Error : 32|16@1+ (1,0) [0|0] "mV" Vector__XXX
        SG_ Total_Pack_Capacity : 48|16@1+ (1,0) [0|0] "Ah" Vector__XXX

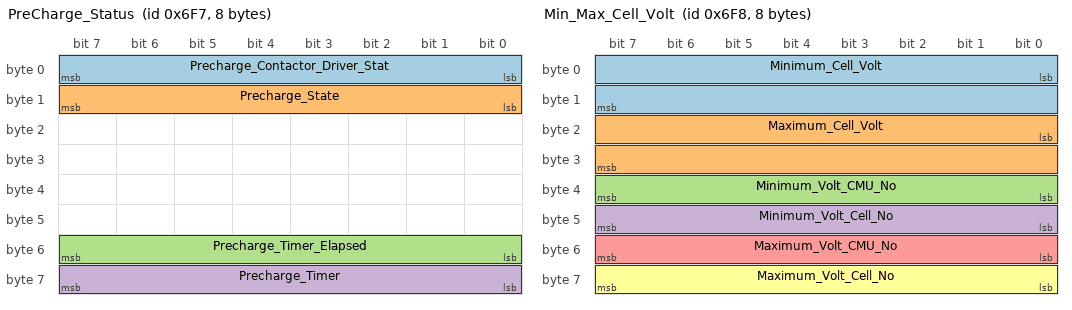
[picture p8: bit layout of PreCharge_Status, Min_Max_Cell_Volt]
BO_ 1783 PreCharge_Status: 8 Vector__XXX
        SG_ Precharge_Contactor_Driver_Stat : 0|8@1+ (1,0) [0|0] "" Vector__XXX
        SG_ Precharge_State : 8|8@1+ (1,0) [0|0] "" Vector__XXX
        SG_ Precharge_Timer_Elapsed : 48|8@1+ (1,0) [0|0] "" Vector__XXX
        SG_ Precharge_Timer : 56|8@1+ (1,10) [0|0] "ms" Vector__XXX

BO_ 1784 Min_Max_Cell_Volt: 8 Vector__XXX
        SG_ Minimum_Cell_Volt : 0|16@1+ (1,0) [0|0] "mV" Vector__XXX
        SG_ Maximum_Cell_Volt : 16|16@1+ (1,0) [0|0] "mV" Vector__XXX
        SG_ Minimum_Volt_CMU_No : 32|8@1+ (1,0) [0|0] "" Vector__XXX
        SG_ Minimum_Volt_Cell_No : 40|8@1+ (1,0) [0|0] "" Vector__XXX
        SG_ Maximum_Volt_CMU_No : 48|8@1+ (1,0) [0|0] "" Vector__XXX
        SG_ Maximum_Volt_Cell_No : 56|8@1+ (1,0) [0|0] "" Vector__XXX

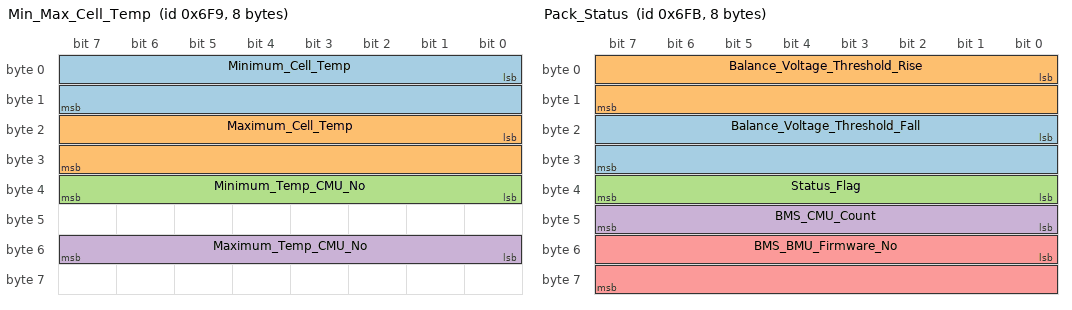
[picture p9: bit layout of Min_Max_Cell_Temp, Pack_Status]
BO_ 1785 Min_Max_Cell_Temp: 8 Vector__XXX
        SG_ Minimum_Cell_Temp : 0|16@1+ (0.1,0) [0|0] "Celcius" Vector__XXX
        SG_ Maximum_Cell_Temp : 16|16@1+ (0.1,0) [0|0] "Celcius" Vector__XXX
        SG_ Minimum_Temp_CMU_No : 32|8@1+ (1,0) [0|0] "" Vector__XXX
        SG_ Maximum_Temp_CMU_No : 48|8@1+ (1,0) [0|0] "" Vector__XXX

BO_ 1786 Battery_Volt_Current: 8 Vector__XXX
        SG_ Battery_Voltage : 0|32@1+ (1,0) [0|0] "mV" Vector__XXX
        SG_ Battery_Current : 32|32@1+ (1,0) [0|0] "mA" Vector__XXX

BO_ 1787 Pack_Status: 8 Vector__XXX
        SG_ Balance_Voltage_Threshold_Fall : 16|16@1+ (1,0) [0|0] "" Vector__XXX
        SG_ Balance_Voltage_Threshold_Rise : 0|16@1+ (1,0) [0|0] "" Vector__XXX
        SG_ Status_Flag : 32|8@1+ (1,0) [0|0] "" Vector__XXX
        SG_ BMS_CMU_Count : 40|8@1+ (1,0) [0|0] "" Vector__XXX
        SG_ BMS_BMU_Firmware_No : 48|16@1+ (1,0) [0|0] "" Vector__XXX

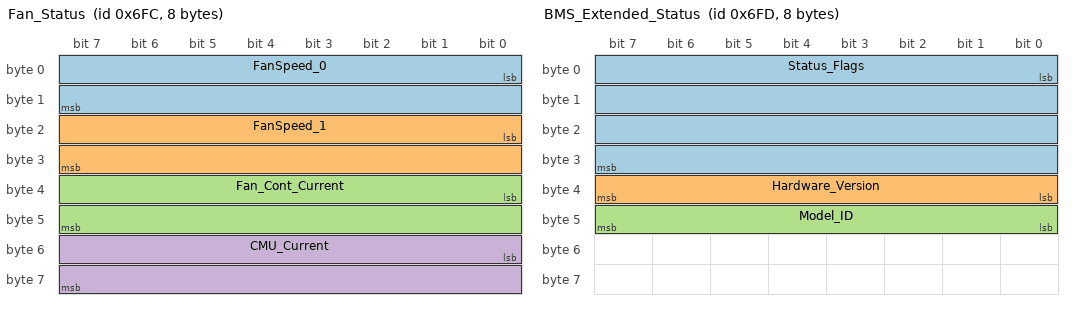
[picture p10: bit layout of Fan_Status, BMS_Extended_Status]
BO_ 1788 Fan_Status: 8 Vector__XXX
        SG_ FanSpeed_0 : 0|16@1+ (1,0) [0|0] "rpm" Vector__XXX
        SG_ FanSpeed_1 : 16|16@1+ (1,0) [0|0] "rpm" Vector__XXX
        SG_ Fan_Cont_Current : 32|16@1+ (1,0) [0|0] "mA" Vector__XXX
        SG_ CMU_Current : 48|16@1+ (1,0) [0|0] "mA" Vector__XXX

BO_ 1789 BMS_Extended_Status: 8 Vector__XXX
        SG_ Status_Flags : 0|32@1+ (1,0) [0|0] "" Vector__XXX
        SG_ Hardware_Version : 32|8@1+ (1,0) [0|0] "" Vector__XXX
        SG_ Model_ID : 40|8@1+ (1,0) [0|0] "" Vector__XXX

BA_DEF_  "BusType" STRING ;
BA_DEF_DEF_  "BusType" "";
BA_ "BusType" "CAN";

SIG_VALTYPE_ 1026 Bus_Voltage : 1;
SIG_VALTYPE_ 1026 Bus_Current : 1;
SIG_VALTYPE_ 1027 Motor_Velocity : 1;
SIG_VALTYPE_ 1027 Vehicle_Velocity : 1;
SIG_VALTYPE_ 1028 PhaseC_Current_Val : 1;
SIG_VALTYPE_ 1028 PhaseB_Current_Val : 1;
SIG_VALTYPE_ 1029 Vq : 1;
SIG_VALTYPE_ 1029 Vd : 1;
SIG_VALTYPE_ 1030 Iq : 1;
SIG_VALTYPE_ 1030 Id : 1;
SIG_VALTYPE_ 1031 BEMFq : 1;
SIG_VALTYPE_ 1031 BEMFd : 1;
SIG_VALTYPE_ 1032 Supply_15V : 1;
SIG_VALTYPE_ 1033 Supply_1V9 : 1;
SIG_VALTYPE_ 1033 Supply_3V3 : 1;
SIG_VALTYPE_ 1035 Motor_Temp : 1;
SIG_VALTYPE_ 1035 Heat_Sink_Temp : 1;
SIG_VALTYPE_ 1036 DSP_Board_Temperature : 1;
SIG_VALTYPE_ 1038 Odometer : 1;
SIG_VALTYPE_ 1038 DC_Bus_AmpHours : 1;
SIG_VALTYPE_ 1047 Slip_Speed : 1;

SIG_VALTYPE_ 1696 Input_Voltage_A : 1;
SIG_VALTYPE_ 1696 Input_Current_A : 1;
SIG_VALTYPE_ 1697 Output_Voltage_A : 1;
SIG_VALTYPE_ 1697 Output_Current_A : 1;
SIG_VALTYPE_ 1698 MOSFET_Temp_A : 1;
SIG_VALTYPE_ 1698 Controller_Temp_A : 1;
SIG_VALTYPE_ 1699 Supply_12V_A : 1;
SIG_VALTYPE_ 1699 Supply_3V_A : 1;
SIG_VALTYPE_ 1700 Max_Out_Volt_A : 1;
SIG_VALTYPE_ 1700 Max_In_Current_A : 1;
SIG_VALTYPE_ 1702 Battery_Side_Output_Voltage_A : 1;
SIG_VALTYPE_ 1702 Power_Connector_Temperature_A : 1;
SIG_VALTYPE_ 1706 Max_Output_Voltage_Set_A : 1;
SIG_VALTYPE_ 1707 Max_Input_Current_Set_A : 1;

SIG_VALTYPE_ 1712 Input_Voltage_B : 1;
SIG_VALTYPE_ 1712 Input_Current_B : 1;
SIG_VALTYPE_ 1713 Output_Voltage_B : 1;
SIG_VALTYPE_ 1713 Output_Current_B : 1;
SIG_VALTYPE_ 1714 MOSFET_Temp_B : 1;
SIG_VALTYPE_ 1714 Controller_Temp_B : 1;
SIG_VALTYPE_ 1715 Supply_12V_B : 1;
SIG_VALTYPE_ 1715 Supply_3V_B : 1;
SIG_VALTYPE_ 1716 Max_Out_Volt_B : 1;
SIG_VALTYPE_ 1716 Max_In_Current_B : 1;
SIG_VALTYPE_ 1718 Battery_Side_Output_Voltage_B : 1;
SIG_VALTYPE_ 1718 Power_Connector_Temperature_B : 1;
SIG_VALTYPE_ 1722 Max_Output_Voltage_Set_B : 1;
SIG_VALTYPE_ 1723 Max_Input_Current_Set_B : 1;

SIG_VALTYPE_ 1728 Input_Voltage_C : 1;
SIG_VALTYPE_ 1728 Input_Current_C : 1;
SIG_VALTYPE_ 1729 Output_Voltage_C : 1;
SIG_VALTYPE_ 1730 MOSFET_Temp_C : 1;
SIG_VALTYPE_ 1730 Controller_Temp_C : 1;
SIG_VALTYPE_ 1731 Supply_12V_C : 1;
SIG_VALTYPE_ 1731 Supply_3V_C : 1;
SIG_VALTYPE_ 1732 Max_Out_Volt_C : 1;
SIG_VALTYPE_ 1732 Max_In_Current_C : 1;
SIG_VALTYPE_ 1734 Battery_Side_Output_Voltage_C : 1;
SIG_VALTYPE_ 1734 Power_Connector_Temperature_C : 1;
SIG_VALTYPE_ 1738 Max_Output_Voltage_Set_C : 1;
SIG_VALTYPE_ 1739 Max_Input_Current_Set_C : 1;

SIG_VALTYPE_ 1744 Input_Voltage_D : 1;
SIG_VALTYPE_ 1744 Input_Current_D : 1;
SIG_VALTYPE_ 1745 Output_Voltage_D : 1;
SIG_VALTYPE_ 1745 Output_Current_D : 1;
SIG_VALTYPE_ 1746 MOSFET_Temp_D : 1;
SIG_VALTYPE_ 1746 Controller_Temp_ : 1;
SIG_VALTYPE_ 1747 Supply_12V_D : 1;
SIG_VALTYPE_ 1747 Supply_3V_D : 1;
SIG_VALTYPE_ 1748 Max_Out_Volt_D : 1;
SIG_VALTYPE_ 1748 Max_In_Current_D : 1;
SIG_VALTYPE_ 1750 Battery_Side_Output_Voltage_D : 1;
SIG_VALTYPE_ 1750 Power_Connector_Temperature_D : 1;
SIG_VALTYPE_ 1754 Max_Output_Voltage_Set_D : 1;
SIG_VALTYPE_ 1755 Max_Input_Current_Set_D : 1;

SIG_VALTYPE_ 1780 SOC_Ah : 1;
SIG_VALTYPE_ 1780 SOC_Percent : 1;
SIG_VALTYPE_ 1781 SOC_Ah : 1;
SIG_VALTYPE_ 1781 SOC_Percent : 1;
